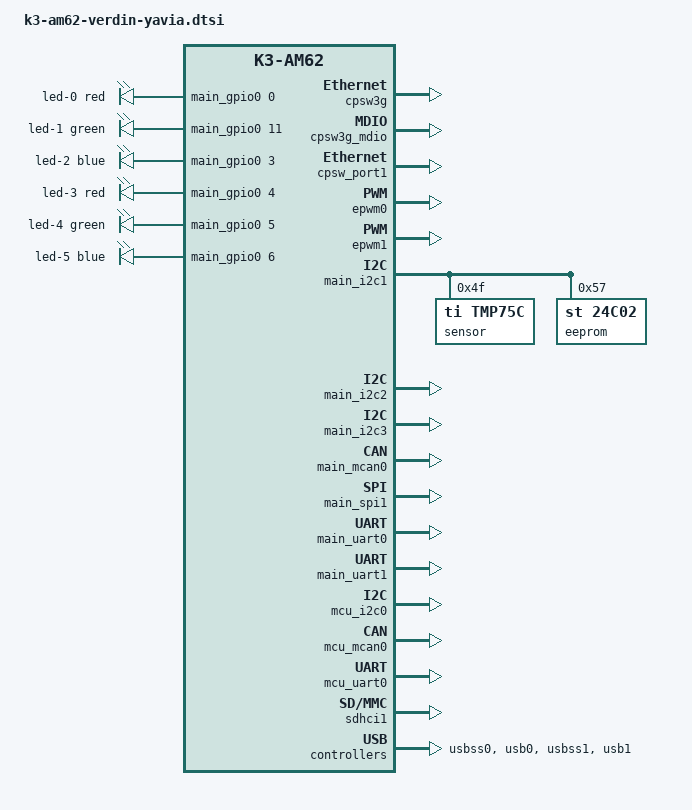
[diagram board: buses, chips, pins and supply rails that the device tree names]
#include <dt-bindings/leds/common.h>
/ {
	leds {
		compatible = "gpio-leds";
		pinctrl-names = "default";
		pinctrl-0 = <&pinctrl_qspi1_clk_gpio>,
			    <&pinctrl_qspi1_cs_gpio>,
			    <&pinctrl_qspi1_io0_gpio>,
			    <&pinctrl_qspi1_io1_gpio>,
			    <&pinctrl_qspi1_io2_gpio>,
			    <&pinctrl_qspi1_io3_gpio>;
		led-0 {
			color = <LED_COLOR_ID_RED>;
			function = LED_FUNCTION_DEBUG;
			function-enumerator = <1>;
			gpios = <&main_gpio0 0 GPIO_ACTIVE_HIGH>;
		};
		led-1 {
			color = <LED_COLOR_ID_GREEN>;
			function = LED_FUNCTION_DEBUG;
			function-enumerator = <1>;
			gpios = <&main_gpio0 11 GPIO_ACTIVE_HIGH>;
		};
		led-2 {
			color = <LED_COLOR_ID_BLUE>;
			function = LED_FUNCTION_DEBUG;
			function-enumerator = <1>;
			gpios = <&main_gpio0 3 GPIO_ACTIVE_HIGH>;
		};
		led-3 {
			color = <LED_COLOR_ID_RED>;
			function = LED_FUNCTION_DEBUG;
			function-enumerator = <2>;
			gpios = <&main_gpio0 4 GPIO_ACTIVE_HIGH>;
		};
		led-4 {
			color = <LED_COLOR_ID_GREEN>;
			function = LED_FUNCTION_DEBUG;
			function-enumerator = <2>;
			gpios = <&main_gpio0 5 GPIO_ACTIVE_HIGH>;
		};
		led-5 {
			color = <LED_COLOR_ID_BLUE>;
			function = LED_FUNCTION_DEBUG;
			function-enumerator = <2>;
			gpios = <&main_gpio0 6 GPIO_ACTIVE_HIGH>;
		};
	};
};
&cpsw3g {
	status = "okay";
};
&cpsw3g_mdio {
	status = "okay";
};
&cpsw_port1 {
	status = "okay";
};
&epwm0 {
	status = "okay";
};
&epwm1 {
	status = "okay";
};
&main_gpio0 {
	pinctrl-names = "default";
	pinctrl-0 = <&pinctrl_ctrl_sleep_moci>,
		    <&pinctrl_gpio_5>,
		    <&pinctrl_gpio_6>,
		    <&pinctrl_gpio_7>,
		    <&pinctrl_gpio_8>,
		    <&pinctrl_qspi1_cs2_gpio>;
};
&main_gpio1 {
	pinctrl-names = "default";
	pinctrl-0 = <&pinctrl_qspi1_dqs_gpio>;
};
&main_i2c1 {
	status = "okay";
	sensor@4f {
		compatible = "ti,tmp75c";
		reg = <0x4f>;
	};
	eeprom@57 {
		compatible = "st,24c02";
		reg = <0x57>;
		pagesize = <16>;
	};
};
&main_i2c2 {
	status = "okay";
};
&main_i2c3 {
	status = "okay";
};
&main_mcan0 {
	status = "okay";
};
&main_spi1 {
	status = "okay";
};
&main_uart0 {
	status = "okay";
};
&main_uart1 {
	status = "okay";
};
&mcu_gpio0 {
	pinctrl-names = "default";
	pinctrl-0 = <&pinctrl_gpio_1>,
		    <&pinctrl_gpio_2>,
		    <&pinctrl_gpio_3>,
		    <&pinctrl_gpio_4>;
};
&mcu_i2c0 {
	status = "okay";
};
&mcu_mcan0 {
	status = "okay";
};
&mcu_uart0 {
	status = "okay";
};
&sdhci1 {
	status = "okay";
};
&usbss0 {
	status = "okay";
};
&usb0 {
	status = "okay";
};
&usbss1 {
	status = "okay";
};
&usb1 {
	status = "okay";
};
&verdin_gpio_keys {
	status = "okay";
};
&wkup_uart0 {
	status = "reserved";
};
